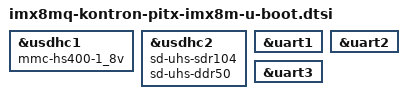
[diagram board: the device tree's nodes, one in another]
// SPDX-License-Identifier: (GPL-2.0 OR MIT)

#include "imx8mq-u-boot.dtsi"

&usdhc1 {
	mmc-hs400-1_8v;
};

&usdhc2 {
	sd-uhs-sdr104;
	sd-uhs-ddr50;
};

&uart1 {
	/delete-property/ assigned-clocks;
	/delete-property/ assigned-clock-parents;
};

&uart2 {
	/delete-property/ assigned-clocks;
	/delete-property/ assigned-clock-parents;
};

&uart3 {
	/delete-property/ assigned-clocks;
	/delete-property/ assigned-clock-parents;
};
